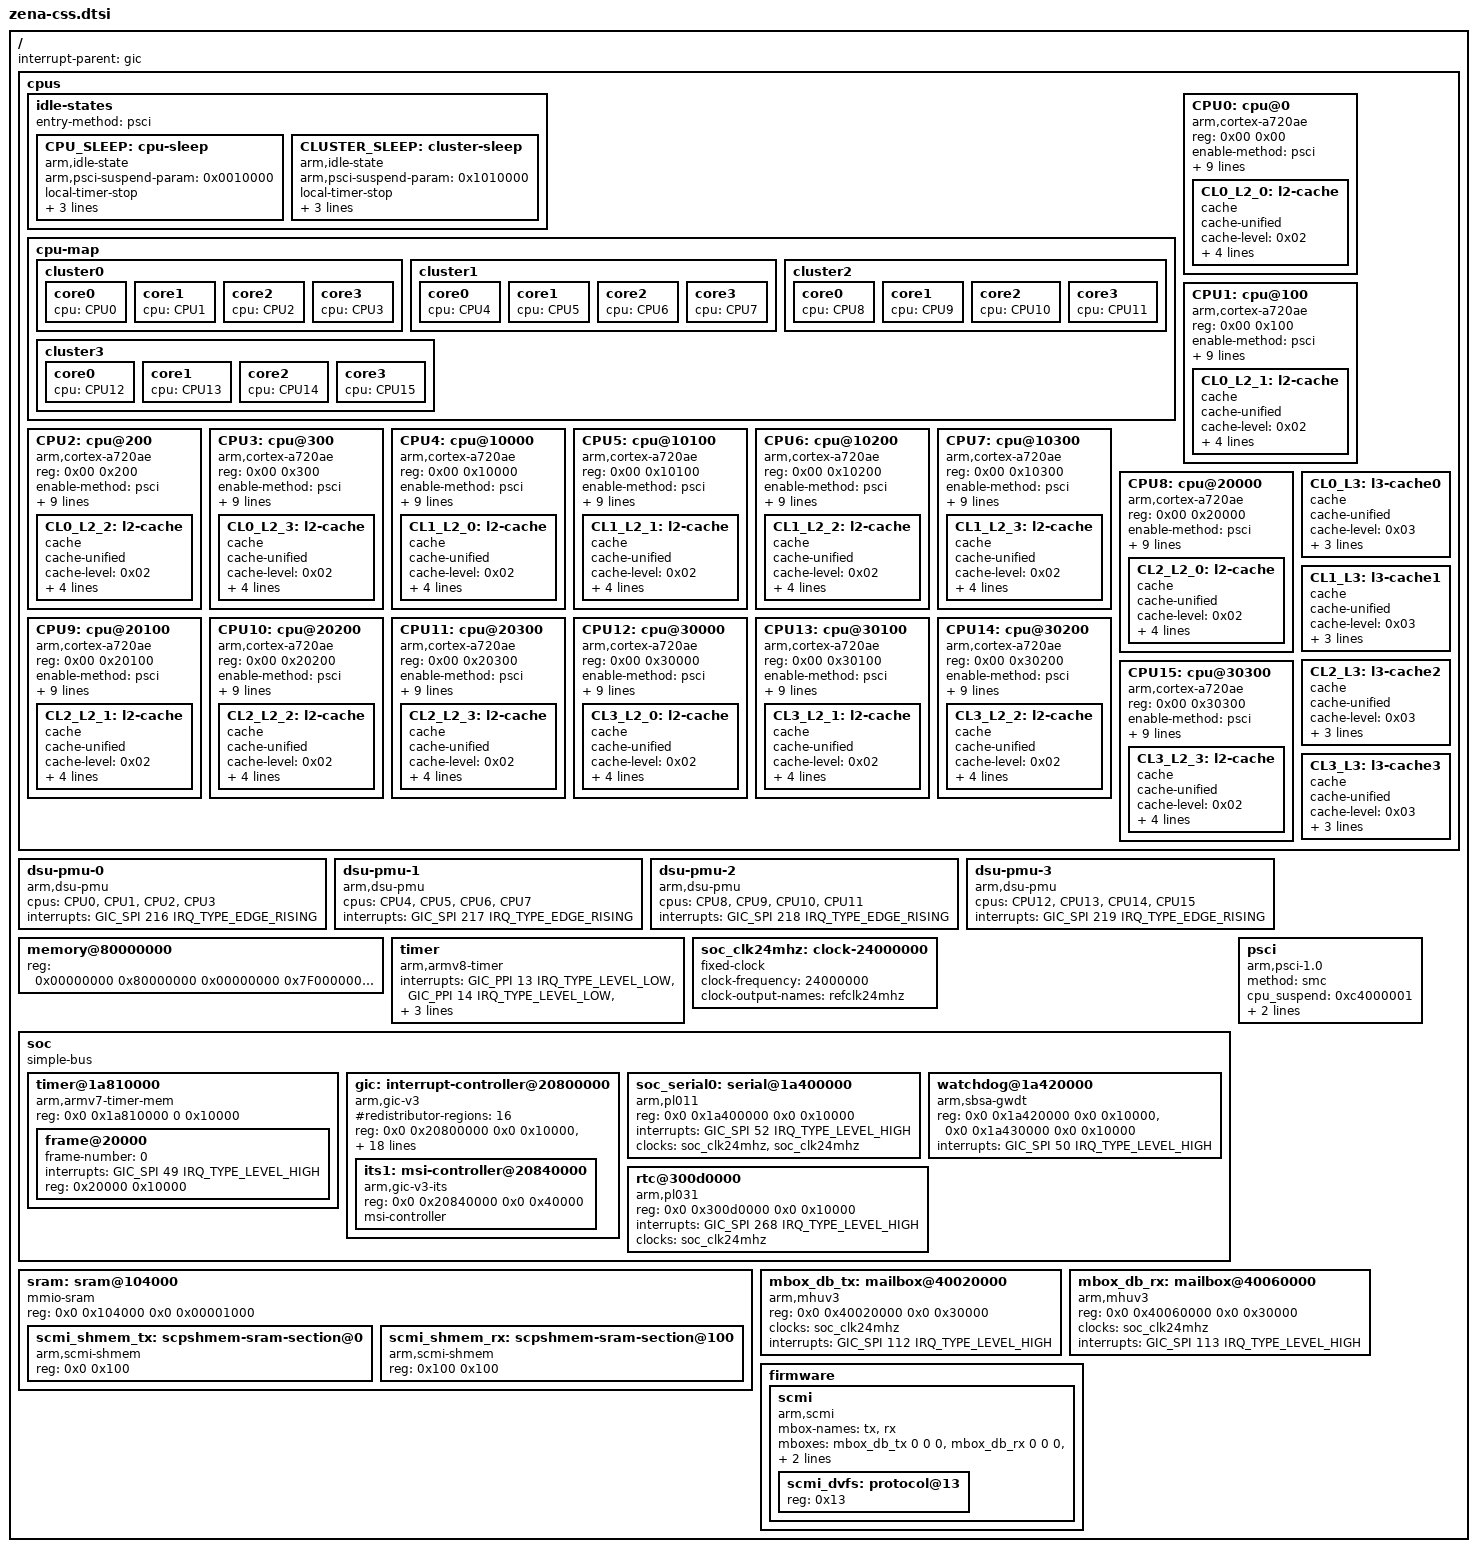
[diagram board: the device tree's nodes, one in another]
// SPDX-License-Identifier: (GPL-2.0 OR BSD-3-Clause)
/*
 * Copyright (c) 2025, Arm Limited. All rights reserved.
 */

#include <dt-bindings/interrupt-controller/arm-gic.h>

/ {
	interrupt-parent = <&gic>;
	#address-cells = <2>;
	#size-cells = <2>;

	cpus {
		#address-cells = <2>;
		#size-cells = <0>;

		/*
		 * The latency and residency numbers below are for illustrative
		 * purpose only and may vary on actual silicon. These values are
		 * considered just to demonstrate that the cpuidle governor
		 * logic works.
		 */
		idle-states {
			entry-method = "psci";

			CPU_SLEEP: cpu-sleep {
				compatible = "arm,idle-state";
				arm,psci-suspend-param = <0x0010000>;
				local-timer-stop;
				entry-latency-us = <800>;
				exit-latency-us = <3200>;
				min-residency-us = <4200>;
			};
			CLUSTER_SLEEP: cluster-sleep {
				compatible = "arm,idle-state";
				arm,psci-suspend-param = <0x1010000>;
				local-timer-stop;
				entry-latency-us = <1000>;
				exit-latency-us = <3200>;
				min-residency-us = <4500>;
			};
		};

		cpu-map {

			cluster0 {

				core0 {
					cpu = <&CPU0>;
				};

				core1 {
					cpu = <&CPU1>;
				};

				core2 {
					cpu = <&CPU2>;
				};

				core3 {
					cpu = <&CPU3>;
				};
			};

			cluster1 {

				core0 {
					cpu = <&CPU4>;
				};

				core1 {
					cpu = <&CPU5>;
				};

				core2 {
					cpu = <&CPU6>;
				};

				core3 {
					cpu = <&CPU7>;
				};
			};

			cluster2 {

				core0 {
					cpu = <&CPU8>;
				};

				core1 {
					cpu = <&CPU9>;
				};

				core2 {
					cpu = <&CPU10>;
				};

				core3 {
					cpu = <&CPU11>;
				};
			};

			cluster3 {

				core0 {
					cpu = <&CPU12>;
				};

				core1 {
					cpu = <&CPU13>;
				};

				core2 {
					cpu = <&CPU14>;
				};

				core3 {
					cpu = <&CPU15>;
				};
			};
		};

		CPU0: cpu@0 {
			device_type = "cpu";
			compatible = "arm,cortex-a720ae";
			reg = <0x00 0x00>;
			enable-method = "psci";
			i-cache-size = <0x10000>;
			i-cache-line-size = <0x40>;
			i-cache-sets = <0x100>;
			d-cache-size = <0x10000>;
			d-cache-line-size = <0x40>;
			d-cache-sets = <0x100>;
			clocks = <&scmi_dvfs 0x00>;
			cpu-idle-states = <&CPU_SLEEP &CLUSTER_SLEEP>;
			next-level-cache = <&CL0_L2_0>;

			CL0_L2_0: l2-cache {
				compatible = "cache";
				cache-unified;
				cache-level = <0x02>;
				/* 512KB */
				cache-size = <0x80000>;
				/* 64B */
				cache-line-size = <0x40>;
				/* 8-way set */
				cache-sets = <0x400>;
				next-level-cache = <&CL0_L3>;
			};
		};

		CPU1: cpu@100 {
			device_type = "cpu";
			compatible = "arm,cortex-a720ae";
			reg = <0x00 0x100>;
			enable-method = "psci";
			i-cache-size = <0x10000>;
			i-cache-line-size = <0x40>;
			i-cache-sets = <0x100>;
			d-cache-size = <0x10000>;
			d-cache-line-size = <0x40>;
			d-cache-sets = <0x100>;
			clocks = <&scmi_dvfs 0x00>;
			cpu-idle-states = <&CPU_SLEEP &CLUSTER_SLEEP>;
			next-level-cache = <&CL0_L2_1>;

			CL0_L2_1: l2-cache {
				compatible = "cache";
				cache-unified;
				cache-level = <0x02>;
				/* 512KB */
				cache-size = <0x80000>;
				/* 64B */
				cache-line-size = <0x40>;
				/* 8-way set */
				cache-sets = <0x400>;
				next-level-cache = <&CL0_L3>;
			};
		};

		CPU2: cpu@200 {
			device_type = "cpu";
			compatible = "arm,cortex-a720ae";
			reg = <0x00 0x200>;
			enable-method = "psci";
			i-cache-size = <0x10000>;
			i-cache-line-size = <0x40>;
			i-cache-sets = <0x100>;
			d-cache-size = <0x10000>;
			d-cache-line-size = <0x40>;
			d-cache-sets = <0x100>;
			clocks = <&scmi_dvfs 0x00>;
			cpu-idle-states = <&CPU_SLEEP &CLUSTER_SLEEP>;
			next-level-cache = <&CL0_L2_2>;

			CL0_L2_2: l2-cache {
				compatible = "cache";
				cache-unified;
				cache-level = <0x02>;
				/* 512KB */
				cache-size = <0x80000>;
				/* 64B */
				cache-line-size = <0x40>;
				/* 8-way set */
				cache-sets = <0x400>;
				next-level-cache = <&CL0_L3>;
			};
		};

		CPU3: cpu@300 {
			device_type = "cpu";
			compatible = "arm,cortex-a720ae";
			reg = <0x00 0x300>;
			enable-method = "psci";
			i-cache-size = <0x10000>;
			i-cache-line-size = <0x40>;
			i-cache-sets = <0x100>;
			d-cache-size = <0x10000>;
			d-cache-line-size = <0x40>;
			d-cache-sets = <0x100>;
			clocks = <&scmi_dvfs 0x00>;
			cpu-idle-states = <&CPU_SLEEP &CLUSTER_SLEEP>;
			next-level-cache = <&CL0_L2_3>;

			CL0_L2_3: l2-cache {
				compatible = "cache";
				cache-unified;
				cache-level = <0x02>;
				/* 512KB */
				cache-size = <0x80000>;
				/* 64B */
				cache-line-size = <0x40>;
				/* 8-way set */
				cache-sets = <0x400>;
				next-level-cache = <&CL0_L3>;
			};
		};

		CPU4: cpu@10000 {
			device_type = "cpu";
			compatible = "arm,cortex-a720ae";
			reg = <0x00 0x10000>;
			enable-method = "psci";
			i-cache-size = <0x10000>;
			i-cache-line-size = <0x40>;
			i-cache-sets = <0x100>;
			d-cache-size = <0x10000>;
			d-cache-line-size = <0x40>;
			d-cache-sets = <0x100>;
			clocks = <&scmi_dvfs 0x00>;
			cpu-idle-states = <&CPU_SLEEP &CLUSTER_SLEEP>;
			next-level-cache = <&CL1_L2_0>;

			CL1_L2_0: l2-cache {
				compatible = "cache";
				cache-unified;
				cache-level = <0x02>;
				/* 512KB */
				cache-size = <0x80000>;
				/* 64B */
				cache-line-size = <0x40>;
				/* 8-way set */
				cache-sets = <0x400>;
				next-level-cache = <&CL1_L3>;
			};
		};

		CPU5: cpu@10100 {
			device_type = "cpu";
			compatible = "arm,cortex-a720ae";
			reg = <0x00 0x10100>;
			enable-method = "psci";
			i-cache-size = <0x10000>;
			i-cache-line-size = <0x40>;
			i-cache-sets = <0x100>;
			d-cache-size = <0x10000>;
			d-cache-line-size = <0x40>;
			d-cache-sets = <0x100>;
			clocks = <&scmi_dvfs 0x00>;
			cpu-idle-states = <&CPU_SLEEP &CLUSTER_SLEEP>;
			next-level-cache = <&CL1_L2_1>;

			CL1_L2_1: l2-cache {
				compatible = "cache";
				cache-unified;
				cache-level = <0x02>;
				/* 512KB */
				cache-size = <0x80000>;
				/* 64B */
				cache-line-size = <0x40>;
				/* 8-way set */
				cache-sets = <0x400>;
				next-level-cache = <&CL1_L3>;
			};
		};

		CPU6: cpu@10200 {
			device_type = "cpu";
			compatible = "arm,cortex-a720ae";
			reg = <0x00 0x10200>;
			enable-method = "psci";
			i-cache-size = <0x10000>;
			i-cache-line-size = <0x40>;
			i-cache-sets = <0x100>;
			d-cache-size = <0x10000>;
			d-cache-line-size = <0x40>;
			d-cache-sets = <0x100>;
			clocks = <&scmi_dvfs 0x00>;
			cpu-idle-states = <&CPU_SLEEP &CLUSTER_SLEEP>;
			next-level-cache = <&CL1_L2_2>;

			CL1_L2_2: l2-cache {
				compatible = "cache";
				cache-unified;
				cache-level = <0x02>;
				/* 512KB */
				cache-size = <0x80000>;
				/* 64B */
				cache-line-size = <0x40>;
				/* 8-way set */
				cache-sets = <0x400>;
				next-level-cache = <&CL1_L3>;
			};
		};

		CPU7: cpu@10300 {
			device_type = "cpu";
			compatible = "arm,cortex-a720ae";
			reg = <0x00 0x10300>;
			enable-method = "psci";
			i-cache-size = <0x10000>;
			i-cache-line-size = <0x40>;
			i-cache-sets = <0x100>;
			d-cache-size = <0x10000>;
			d-cache-line-size = <0x40>;
			d-cache-sets = <0x100>;
			clocks = <&scmi_dvfs 0x00>;
			cpu-idle-states = <&CPU_SLEEP &CLUSTER_SLEEP>;
			next-level-cache = <&CL1_L2_3>;

			CL1_L2_3: l2-cache {
				compatible = "cache";
				cache-unified;
				cache-level = <0x02>;
				/* 512KB */
				cache-size = <0x80000>;
				/* 64B */
				cache-line-size = <0x40>;
				/* 8-way set */
				cache-sets = <0x400>;
				next-level-cache = <&CL1_L3>;
			};
		};

		CPU8: cpu@20000 {
			device_type = "cpu";
			compatible = "arm,cortex-a720ae";
			reg = <0x00 0x20000>;
			enable-method = "psci";
			i-cache-size = <0x10000>;
			i-cache-line-size = <0x40>;
			i-cache-sets = <0x100>;
			d-cache-size = <0x10000>;
			d-cache-line-size = <0x40>;
			d-cache-sets = <0x100>;
			clocks = <&scmi_dvfs 0x00>;
			cpu-idle-states = <&CPU_SLEEP &CLUSTER_SLEEP>;
			next-level-cache = <&CL2_L2_0>;

			CL2_L2_0: l2-cache {
				compatible = "cache";
				cache-unified;
				cache-level = <0x02>;
				/* 512KB */
				cache-size = <0x80000>;
				/* 64B */
				cache-line-size = <0x40>;
				/* 8-way set */
				cache-sets = <0x400>;
				next-level-cache = <&CL2_L3>;
			};
		};

		CPU9: cpu@20100 {
			device_type = "cpu";
			compatible = "arm,cortex-a720ae";
			reg = <0x00 0x20100>;
			enable-method = "psci";
			i-cache-size = <0x10000>;
			i-cache-line-size = <0x40>;
			i-cache-sets = <0x100>;
			d-cache-size = <0x10000>;
			d-cache-line-size = <0x40>;
			d-cache-sets = <0x100>;
			clocks = <&scmi_dvfs 0x00>;
			cpu-idle-states = <&CPU_SLEEP &CLUSTER_SLEEP>;
			next-level-cache = <&CL2_L2_1>;

			CL2_L2_1: l2-cache {
				compatible = "cache";
				cache-unified;
				cache-level = <0x02>;
				/* 512KB */
				cache-size = <0x80000>;
				/* 64B */
				cache-line-size = <0x40>;
				/* 8-way set */
				cache-sets = <0x400>;
				next-level-cache = <&CL2_L3>;
			};
		};

		CPU10: cpu@20200 {
			device_type = "cpu";
			compatible = "arm,cortex-a720ae";
			reg = <0x00 0x20200>;
			enable-method = "psci";
			i-cache-size = <0x10000>;
			i-cache-line-size = <0x40>;
			i-cache-sets = <0x100>;
			d-cache-size = <0x10000>;
			d-cache-line-size = <0x40>;
			d-cache-sets = <0x100>;
			clocks = <&scmi_dvfs 0x00>;
			cpu-idle-states = <&CPU_SLEEP &CLUSTER_SLEEP>;
			next-level-cache = <&CL2_L2_2>;

			CL2_L2_2: l2-cache {
				compatible = "cache";
				cache-unified;
				cache-level = <0x02>;
				/* 512KB */
				cache-size = <0x80000>;
				/* 64B */
				cache-line-size = <0x40>;
				/* 8-way set */
				cache-sets = <0x400>;
				next-level-cache = <&CL2_L3>;
			};
		};

		CPU11: cpu@20300 {
			device_type = "cpu";
			compatible = "arm,cortex-a720ae";
			reg = <0x00 0x20300>;
			enable-method = "psci";
			i-cache-size = <0x10000>;
			i-cache-line-size = <0x40>;
			i-cache-sets = <0x100>;
			d-cache-size = <0x10000>;
			d-cache-line-size = <0x40>;
			d-cache-sets = <0x100>;
			clocks = <&scmi_dvfs 0x00>;
			cpu-idle-states = <&CPU_SLEEP &CLUSTER_SLEEP>;
			next-level-cache = <&CL2_L2_3>;

			CL2_L2_3: l2-cache {
				compatible = "cache";
				cache-unified;
				cache-level = <0x02>;
				/* 512KB */
				cache-size = <0x80000>;
				/* 64B */
				cache-line-size = <0x40>;
				/* 8-way set */
				cache-sets = <0x400>;
				next-level-cache = <&CL2_L3>;
			};
		};

		CPU12: cpu@30000 {
			device_type = "cpu";
			compatible = "arm,cortex-a720ae";
			reg = <0x00 0x30000>;
			enable-method = "psci";
			i-cache-size = <0x10000>;
			i-cache-line-size = <0x40>;
			i-cache-sets = <0x100>;
			d-cache-size = <0x10000>;
			d-cache-line-size = <0x40>;
			d-cache-sets = <0x100>;
			clocks = <&scmi_dvfs 0x00>;
			cpu-idle-states = <&CPU_SLEEP &CLUSTER_SLEEP>;
			next-level-cache = <&CL3_L2_0>;

			CL3_L2_0: l2-cache {
				compatible = "cache";
				cache-unified;
				cache-level = <0x02>;
				/* 512KB */
				cache-size = <0x80000>;
				/* 64B */
				cache-line-size = <0x40>;
				/* 8-way set */
				cache-sets = <0x400>;
				next-level-cache = <&CL3_L3>;
			};
		};

		CPU13: cpu@30100 {
			device_type = "cpu";
			compatible = "arm,cortex-a720ae";
			reg = <0x00 0x30100>;
			enable-method = "psci";
			i-cache-size = <0x10000>;
			i-cache-line-size = <0x40>;
			i-cache-sets = <0x100>;
			d-cache-size = <0x10000>;
			d-cache-line-size = <0x40>;
			d-cache-sets = <0x100>;
			clocks = <&scmi_dvfs 0x00>;
			cpu-idle-states = <&CPU_SLEEP &CLUSTER_SLEEP>;
			next-level-cache = <&CL3_L2_1>;

			CL3_L2_1: l2-cache {
				compatible = "cache";
				cache-unified;
				cache-level = <0x02>;
				/* 512KB */
				cache-size = <0x80000>;
				/* 64B */
				cache-line-size = <0x40>;
				/* 8-way set */
				cache-sets = <0x400>;
				next-level-cache = <&CL3_L3>;
			};
		};

		CPU14: cpu@30200 {
			device_type = "cpu";
			compatible = "arm,cortex-a720ae";
			reg = <0x00 0x30200>;
			enable-method = "psci";
			i-cache-size = <0x10000>;
			i-cache-line-size = <0x40>;
			i-cache-sets = <0x100>;
			d-cache-size = <0x10000>;
			d-cache-line-size = <0x40>;
			d-cache-sets = <0x100>;
			clocks = <&scmi_dvfs 0x00>;
			cpu-idle-states = <&CPU_SLEEP &CLUSTER_SLEEP>;
			next-level-cache = <&CL3_L2_2>;

			CL3_L2_2: l2-cache {
				compatible = "cache";
				cache-unified;
				cache-level = <0x02>;
				/* 512KB */
				cache-size = <0x80000>;
				/* 64B */
				cache-line-size = <0x40>;
				/* 8-way set */
				cache-sets = <0x400>;
				next-level-cache = <&CL3_L3>;
			};
		};

		CPU15: cpu@30300 {
			device_type = "cpu";
			compatible = "arm,cortex-a720ae";
			reg = <0x00 0x30300>;
			enable-method = "psci";
			i-cache-size = <0x10000>;
			i-cache-line-size = <0x40>;
			i-cache-sets = <0x100>;
			d-cache-size = <0x10000>;
			d-cache-line-size = <0x40>;
			d-cache-sets = <0x100>;
			clocks = <&scmi_dvfs 0x00>;
			cpu-idle-states = <&CPU_SLEEP &CLUSTER_SLEEP>;
			next-level-cache = <&CL3_L2_3>;

			CL3_L2_3: l2-cache {
				compatible = "cache";
				cache-unified;
				cache-level = <0x02>;
				/* 512KB */
				cache-size = <0x80000>;
				/* 64B */
				cache-line-size = <0x40>;
				/* 8-way set */
				cache-sets = <0x400>;
				next-level-cache = <&CL3_L3>;
			};
		};

		CL0_L3: l3-cache0 {
			compatible = "cache";
			cache-unified;
			cache-level = <0x03>;
			/* 4MB */
			cache-size = <0x400000>;
			/* 64B */
			cache-line-size = <0x40>;
			/* 16-way set */
			cache-sets = <0x1000>;
		};

		CL1_L3: l3-cache1 {
			compatible = "cache";
			cache-unified;
			cache-level = <0x03>;
			/* 4MB */
			cache-size = <0x400000>;
			/* 64B */
			cache-line-size = <0x40>;
			/* 16-way set */
			cache-sets = <0x1000>;
		};

		CL2_L3: l3-cache2 {
			compatible = "cache";
			cache-unified;
			cache-level = <0x03>;
			/* 4MB */
			cache-size = <0x400000>;
			/* 64B */
			cache-line-size = <0x40>;
			/* 16-way set */
			cache-sets = <0x1000>;
		};

		CL3_L3: l3-cache3 {
			compatible = "cache";
			cache-unified;
			cache-level = <0x03>;
			/* 4MB */
			cache-size = <0x400000>;
			/* 64B */
			cache-line-size = <0x40>;
			/* 16-way set */
			cache-sets = <0x1000>;
		};
	};

	dsu-pmu-0 {
		compatible = "arm,dsu-pmu";
		cpus = <&CPU0 &CPU1 &CPU2 &CPU3>;
		interrupts = <GIC_SPI 216 IRQ_TYPE_EDGE_RISING>;
	};

	dsu-pmu-1 {
		compatible = "arm,dsu-pmu";
		cpus = <&CPU4 &CPU5 &CPU6 &CPU7>;
		interrupts = <GIC_SPI 217 IRQ_TYPE_EDGE_RISING>;
	};

	dsu-pmu-2 {
		compatible = "arm,dsu-pmu";
		cpus = <&CPU8 &CPU9 &CPU10 &CPU11>;
		interrupts = <GIC_SPI 218 IRQ_TYPE_EDGE_RISING>;
	};

	dsu-pmu-3 {
		compatible = "arm,dsu-pmu";
		cpus = <&CPU12 &CPU13 &CPU14 &CPU15>;
		interrupts = <GIC_SPI 219 IRQ_TYPE_EDGE_RISING>;
	};

	memory@80000000 {
		device_type = "memory";

		/* Bank 0: start = 0x0000_0000_8000_0000, size = ~2 GiB (0x7F00_0000) */
		reg = <
			0x00000000  0x80000000  0x00000000  0x7F000000
			0x00000200  0x00000000  0x00000000  0x80000000
		>;
	};

	timer {
		compatible = "arm,armv8-timer";
		interrupts = <GIC_PPI 13 IRQ_TYPE_LEVEL_LOW>,
			<GIC_PPI 14 IRQ_TYPE_LEVEL_LOW>,
			<GIC_PPI 11 IRQ_TYPE_LEVEL_LOW>,
			<GIC_PPI 10 IRQ_TYPE_LEVEL_LOW>,
			<GIC_PPI 12 IRQ_TYPE_LEVEL_LOW>;
	};

	soc_clk24mhz: clock-24000000 {
		compatible = "fixed-clock";
		#clock-cells = <0>;
		clock-frequency = <24000000>;
		clock-output-names = "refclk24mhz";
	};

	soc: soc {
		compatible = "simple-bus";
		#address-cells = <2>;
		#size-cells = <2>;
		ranges;

		timer@1a810000 {
			compatible = "arm,armv7-timer-mem";
			reg = <0x0 0x1a810000 0 0x10000>;
			#address-cells = <1>;
			#size-cells = <1>;
			/* Map child space [0x0..0x30000) to parent @ 0x1a810000 */
			ranges = <0x0 0x0 0x1a810000 0x00030000>;

			frame@20000 {
				frame-number = <0>;
				interrupts = <GIC_SPI 49 IRQ_TYPE_LEVEL_HIGH>;
				reg = <0x20000 0x10000>;
			};
		};

		gic: interrupt-controller@20800000 {
			compatible = "arm,gic-v3";
			#redistributor-regions = <16>;
			reg = <0x0 0x20800000 0x0 0x10000>,    /* GICD */
				<0x0 0x20880000 0x0 0x40000>,    /* 16 * GICR */
				<0x0 0x208c0000 0x0 0x40000>,
				<0x0 0x20900000 0x0 0x40000>,
				<0x0 0x20940000 0x0 0x40000>,
				<0x0 0x20980000 0x0 0x40000>,
				<0x0 0x209c0000 0x0 0x40000>,
				<0x0 0x20a00000 0x0 0x40000>,
				<0x0 0x20a40000 0x0 0x40000>,
				<0x0 0x20a80000 0x0 0x40000>,
				<0x0 0x20ac0000 0x0 0x40000>,
				<0x0 0x20b00000 0x0 0x40000>,
				<0x0 0x20b40000 0x0 0x40000>,
				<0x0 0x20b80000 0x0 0x40000>,
				<0x0 0x20bc0000 0x0 0x40000>,
				<0x0 0x20c00000 0x0 0x40000>,
				<0x0 0x20c40000 0x0 0x40000>;
			#interrupt-cells = <3>;
			#address-cells = <2>;
			#size-cells = <2>;
			ranges;
			interrupt-controller;
			interrupts = <GIC_PPI 9 IRQ_TYPE_LEVEL_HIGH>;

			its1: msi-controller@20840000 {
				compatible = "arm,gic-v3-its";
				reg = <0x0 0x20840000 0x0 0x40000>;
				msi-controller;
				#msi-cells = <1>;
			};
		};

		/* UART is fixed as 24MHz, both UARTCLK and PCLK */
		soc_serial0: serial@1a400000 {
			compatible = "arm,pl011", "arm,primecell";
			reg = <0x0 0x1a400000 0x0 0x10000>;
			interrupts = <GIC_SPI 52 IRQ_TYPE_LEVEL_HIGH>;
			clocks = <&soc_clk24mhz>, <&soc_clk24mhz>;
			clock-names = "uartclk", "apb_pclk";
		};

		watchdog@1a420000 {
			compatible = "arm,sbsa-gwdt";
			reg = <0x0 0x1a420000 0x0 0x10000>,
			      <0x0 0x1a430000 0x0 0x10000>;
			interrupts = <GIC_SPI 50 IRQ_TYPE_LEVEL_HIGH>;
		};

		rtc@300d0000 {
			compatible = "arm,pl031", "arm,primecell";
			reg = <0x0 0x300d0000 0x0 0x10000>;
			interrupts = <GIC_SPI 268 IRQ_TYPE_LEVEL_HIGH>;
			clocks = <&soc_clk24mhz>;
			clock-names = "apb_pclk";
		};

	};

	psci {
		compatible = "arm,psci-1.0", "arm,psci-0.2", "arm,psci";
		method = "smc";
		cpu_suspend = <0xc4000001>;
		cpu_off = <0x84000002>;
		cpu_on = <0xc4000003>;
	};

	sram: sram@104000 {
		compatible = "mmio-sram";
		reg = <0x0 0x104000 0x0 0x00001000>;
		#address-cells = <1>;
		#size-cells = <1>;
		ranges = <0 0x0 0x104000 0x00001000>;

		scmi_shmem_tx: scpshmem-sram-section@0 {
			compatible = "arm,scmi-shmem";
			reg = <0x0 0x100>;
		};
		scmi_shmem_rx: scpshmem-sram-section@100 {
			compatible = "arm,scmi-shmem";
			reg = <0x100 0x100>;
		};
	};

	mbox_db_tx: mailbox@40020000 {
		compatible = "arm,mhuv3";
		reg = <0x0 0x40020000 0x0 0x30000>;
		clocks = <&soc_clk24mhz>;
		#mbox-cells = <3>;
		interrupts = <GIC_SPI 112 IRQ_TYPE_LEVEL_HIGH>;
		interrupt-names = "combined";
	};

	mbox_db_rx: mailbox@40060000 {
		compatible = "arm,mhuv3";
		reg = <0x0 0x40060000 0x0 0x30000>;
		clocks = <&soc_clk24mhz>;
		#mbox-cells = <3>;
		interrupts = <GIC_SPI 113 IRQ_TYPE_LEVEL_HIGH>;
		interrupt-names = "combined";
	};

	firmware {
		scmi {
			compatible = "arm,scmi";
			mbox-names = "tx", "rx";
			mboxes = <&mbox_db_tx 0 0 0 &mbox_db_rx 0 0 0 &mbox_db_rx 0 0 2>;
			shmem = <&scmi_shmem_tx &scmi_shmem_rx>;
			#address-cells = <1>;
			#size-cells = <0>;

			scmi_dvfs: protocol@13 {
				reg = <0x13>;
				#clock-cells = <1>;
			};
		};
	};
};
